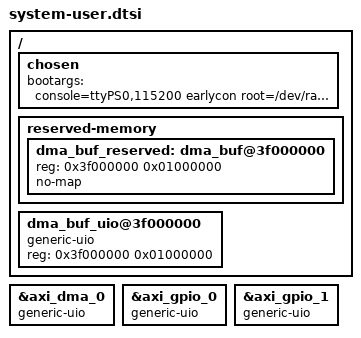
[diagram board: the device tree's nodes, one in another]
/include/ "system-conf.dtsi"

/*
 * system-user.dtsi - Mini-NPU additions to the PetaLinux-generated device tree
 * (Zybo Z7-10, PetaLinux 2023.1)
 *
 * 1. Boot argument that lets the generic UIO driver claim nodes marked "generic-uio".
 * 2. 16 MB of DDR at 0x3F000000 reserved for DMA buffers (Linux never uses it).
 * 3. That buffer, the AXI DMA and both AXI GPIOs exposed to user space as /dev/uioN.
 */

/ {
	chosen {
		/* Default PetaLinux 2023.1 Zynq bootargs + the UIO switch at the end.
		 * Must match what `cat /proc/cmdline` printed on the board before this change. */
		bootargs = "console=ttyPS0,115200 earlycon root=/dev/ram0 rw uio_pdrv_genirq.of_id=generic-uio";
	};

	reserved-memory {
		#address-cells = <1>;
		#size-cells = <1>;
		ranges;

		/* Top 16 MB of the 1 GB DDR3: physical 0x3F000000 - 0x3FFFFFFF */
		dma_buf_reserved: dma_buf@3f000000 {
			reg = <0x3f000000 0x01000000>;
			no-map;
		};
	};

	/* Same 16 MB, handed to user space through UIO (mmap gives an uncached mapping,
	 * so no cache flush/invalidate is needed for DMA buffers). */
	dma_buf_uio@3f000000 {
		compatible = "generic-uio";
		reg = <0x3f000000 0x01000000>;
	};
};

/* AXI DMA registers (0x40400000) for the user-space driver instead of the Linux DMA driver. */
&axi_dma_0 {
	compatible = "generic-uio";
};

/* LEDs + buttons (0x41200000) and switches (0x41210000) */
&axi_gpio_0 {
	compatible = "generic-uio";
};

&axi_gpio_1 {
	compatible = "generic-uio";
};
